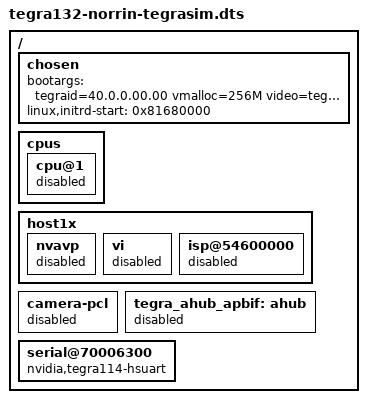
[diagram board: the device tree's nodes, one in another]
#include "tegra132-norrin-pm374-0001-a01-00.dts"


/ {

	chosen {
	        /* other options: debug */
		bootargs = "tegraid=40.0.0.00.00 vmalloc=256M video=tegrafb console=ttyS0,115200n8 earlyprintk=uart8250-32bit,0x70006000 gpt board_info=0x0176:0x0001:0x01:0x43:0x00
displayboard=0xbabe:0x03ea:0x00:0x42:0x00 pmuboard=0x0176:0x0001:0x01:0x43:0x00 no_console_suspend=1";
		linux,initrd-start = <0x81680000>;
	};
	cpus {
		cpu@1 {
			status = "disabled";
		};
	};

        host1x: host1x {
		nvavp {
			status = "disabled";
		};
		vi {
			status = "disabled";
		};
		isp@54600000 {
			status = "disabled";
		};
	};

	camera-pcl {
		status = "disabled";
	};

	tegra_ahub_apbif: ahub {
		status = "disabled";
	};

	serial@70006300 {
		compatible = "nvidia,tegra114-hsuart";
		status = "okay";
	};
};
